# M03_DRAMController register map
Vendor: Babel; File version: 1.0
M03_DRAMController Register Map
CPU: CM0 r0p0, little endian, no MPU, no FPU
Registers are 32-bit, read-write, reset 0x0 unless marked. A register's access mark holds for its fields unless they carry their own. Offsets are from the block's base; lines under a group give offsets from that group; [hi:lo] are bit positions; {n}, {i} and the like mark numbered series; 'fields as' and 'values as' point back to an identical list; <NAME> marks a mode.

## Memory map
0x00000000 M03_DRAMController

## M03_DRAMController
Base 0x00000000
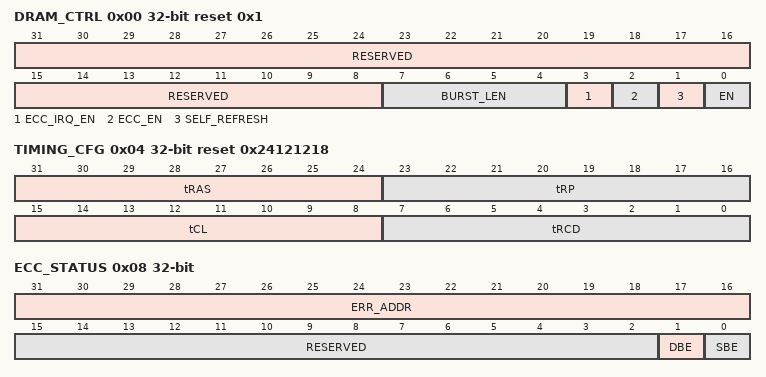
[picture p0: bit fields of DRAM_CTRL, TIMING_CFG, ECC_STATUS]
0x00 DRAM_CTRL reset 0x1 — 控制寄存器：使能、自刷新、ECC
  [31:8] RESERVED - — 保留，必须写 0
  [7:4] BURST_LEN — 突发长度配置（默认 BL8）
  [3] ECC_IRQ_EN — ECC 双比特错误中断使能
  [2] ECC_EN — ECC 使能。1=使能
  [1] SELF_REFRESH — 自刷新模式。1=进入自刷新
  [0] EN — 控制器使能。1=使能，0=禁用
0x04 TIMING_CFG reset 0x24121218 — 时序参数：tRCD、tCL、tRP、tRAS
  [31:24] tRAS — 行激活时间
  [23:16] tRP — 预充电时间
  [15:8] tCL — CAS 延迟
  [7:0] tRCD — 行到列延迟（单位 CLK_SYS）
0x08 ECC_STATUS w1c — ECC 状态：SBE/DBE 标志、错误地址
  [31:16] ERR_ADDR ro — 最近错误地址高 16 位
  [15:2] RESERVED - — 保留
  [1] DBE — 双比特错误标志。写 1 清零
  [0] SBE — 单比特错误标志。写 1 清零
0x0C PERF_CNT ro — 性能计数器
  [31:0] COUNT — 内存访问周期计数
